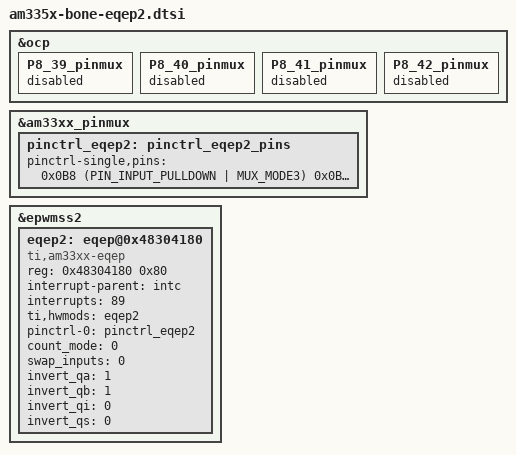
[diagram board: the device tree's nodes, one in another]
/*
 * Copyright (C) 2013 Nathaniel R. Lewis - http://nathanielrlewis.com/
 *
 * This program is free software; you can redistribute it and/or modify
 * it under the terms of the GNU General Public License version 2 as
 * published by the Free Software Foundation.
 * 
 * Enable eQEP2 on the Beaglebone White and Black
 */

&ocp {
	P8_39_pinmux {
		status = "disabled";
	};
	P8_40_pinmux {
		status = "disabled";
	};
	P8_41_pinmux {
		status = "disabled";
	};
	P8_42_pinmux {
		status = "disabled";
	};
};

&am33xx_pinmux {
	pinctrl_eqep2: pinctrl_eqep2_pins {
		pinctrl-single,pins = <
      0x0B8 (PIN_INPUT_PULLDOWN | MUX_MODE3)  /* P8_39 = GPIO2_12 = EQEP2_index, MODE3 */
      0x0BC (PIN_INPUT_PULLDOWN | MUX_MODE3)  /* P8_40 = GPIO2_13 = EQEP2_strobe, MODE3 */
      0x0B0 (PIN_INPUT_PULLDOWN | MUX_MODE3)  /* P8_41 = GPIO2_10 = EQEP2A_in, MODE3 */
      0x0B4 (PIN_INPUT_PULLDOWN | MUX_MODE3)  /* P8_42 = GPIO2_11 = EQEP2B_in, MODE3 */
		>;
	};
};

&epwmss2 {
  status = "okay";

  eqep2: eqep@0x48304180 {
    compatible = "ti,am33xx-eqep";
    reg = <0x48304180 0x80>;
    interrupt-parent = <&intc>;
    interrupts = <89>;
    ti,hwmods = "eqep2";
    status = "okay";

    pinctrl-names = "default";
    pinctrl-0 = <&pinctrl_eqep2>;
    
    count_mode = <0>;  /* 0 - Quadrature mode, normal 90 phase offset cha & chb.  1 - Direction mode.  cha input = clock, chb input = direction */
    swap_inputs = <0>; /* Are channel A and channel B swapped? (0 - no, 1 - yes) */
    invert_qa = <1>;   /* Should we invert the channel A input?  */
    invert_qb = <1>;   /* Should we invert the channel B input? I invert these because my encoder outputs drive transistors that pull down the pins */
    invert_qi = <0>;   /* Should we invert the index input? */
    invert_qs = <0>;   /* Should we invert the strobe input? */
  };
};
